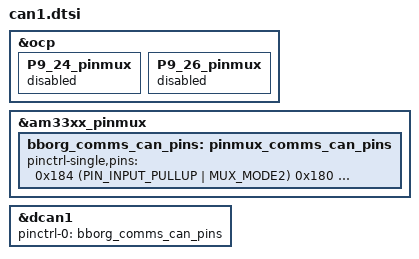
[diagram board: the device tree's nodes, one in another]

#include <dt-bindings/pinctrl/am33xx.h>
#include <dt-bindings/gpio/gpio.h>


&ocp {
	P9_24_pinmux { status = "disabled"; };	/* P9_24: uart1_txd.d_can1_rx */
	P9_26_pinmux { status = "disabled"; };	/* P9_26: uart1_rxd.d_can1_tx */
};

&am33xx_pinmux {
	bborg_comms_can_pins: pinmux_comms_can_pins {
		pinctrl-single,pins = <
			0x184 (PIN_INPUT_PULLUP | MUX_MODE2)	/* P9_24: uart1_txd.d_can1_rx */
			0x180 (PIN_OUTPUT_PULLUP | MUX_MODE2)	/* P9_26: uart1_rxd.d_can1_tx */
		>;
	};
};

&dcan1 {
	status = "okay";
	pinctrl-names = "default";
	pinctrl-0 = <&bborg_comms_can_pins>;
};
